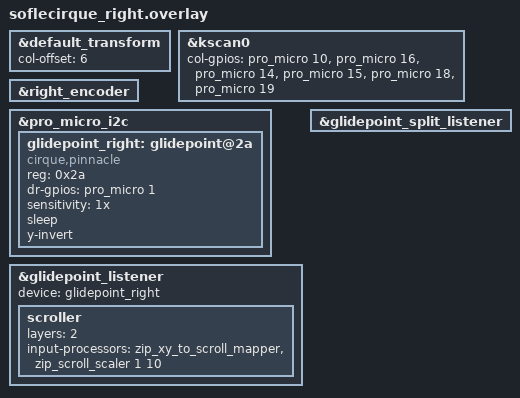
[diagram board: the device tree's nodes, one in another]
/*
 * Copyright (c) 2020 Ryan Cross
 *
 * SPDX-License-Identifier: MIT
 */

#include "soflecirque.dtsi"
#include <input/processors.dtsi>

&default_transform {
    col-offset = <6>;
};

&kscan0 {
    col-gpios
        = <&pro_micro 10 GPIO_ACTIVE_HIGH>
        , <&pro_micro 16 GPIO_ACTIVE_HIGH>
        , <&pro_micro 14 GPIO_ACTIVE_HIGH>
        , <&pro_micro 15 GPIO_ACTIVE_HIGH>
        , <&pro_micro 18 GPIO_ACTIVE_HIGH>
        , <&pro_micro 19 GPIO_ACTIVE_HIGH>
        ;
};

&right_encoder {
    status = "okay";
};

&pro_micro_i2c {
    status = "okay";

    glidepoint_right: glidepoint@2a {
        compatible = "cirque,pinnacle";
        reg = <0x2a>;
        status = "okay";
        dr-gpios = <&pro_micro 1 (GPIO_ACTIVE_HIGH)>;
        sensitivity = "1x";
        sleep;
        //no-taps;
        y-invert;
        //x-invert;
    };
};

&glidepoint_listener {
    status = "okay";
    device = <&glidepoint_right>;

    /* Scroll mode when RAISE layer (2) is active */
    scroller {
        layers = <2>;
        input-processors = <&zip_xy_to_scroll_mapper>, <&zip_scroll_scaler 1 10>;
    };
};

&glidepoint_split_listener {
    status = "okay";
};
